# HT32F175x register map
File version: 1.1
CPU: CM3 r2p0, little endian, no MPU, no FPU, 4 interrupt priority bits
Registers are 32-bit, read-write, reset 0x0 unless marked. A register's access mark holds for its fields unless they carry their own. Offsets are from the block's base; [hi:lo] are bit positions; {n}, {i} and the like mark numbered series.

## GPTM0
Base 0x4006E000
Same registers: GPTM1 0x4006F000
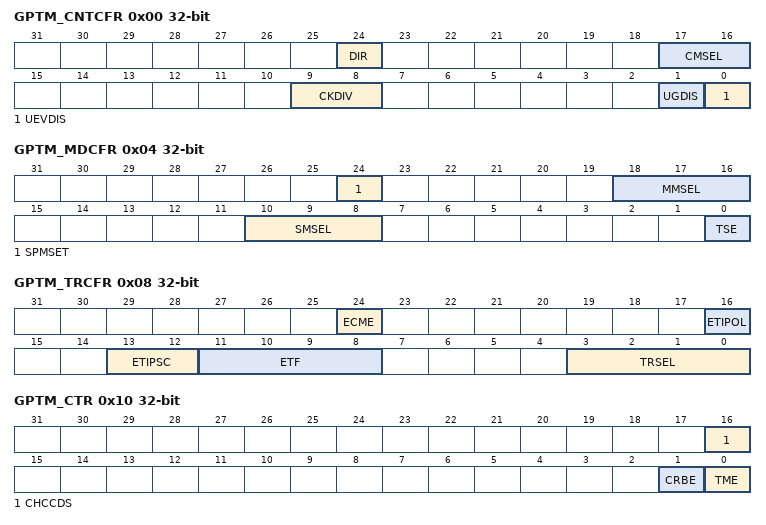
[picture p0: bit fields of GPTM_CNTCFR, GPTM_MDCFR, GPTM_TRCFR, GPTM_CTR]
0x00 GPTM_CNTCFR
  [24] DIR, [17:16] CMSEL, [9:8] CKDIV, [1] UGDIS, [0] UEVDIS
0x04 GPTM_MDCFR
  [24] SPMSET, [18:16] MMSEL, [10:8] SMSEL, [0] TSE
0x08 GPTM_TRCFR
  [24] ECME, [16] ETIPOL, [13:12] ETIPSC, [11:8] ETF, [3:0] TRSEL
0x10 GPTM_CTR
  [16] CHCCDS, [1] CRBE, [0] TME
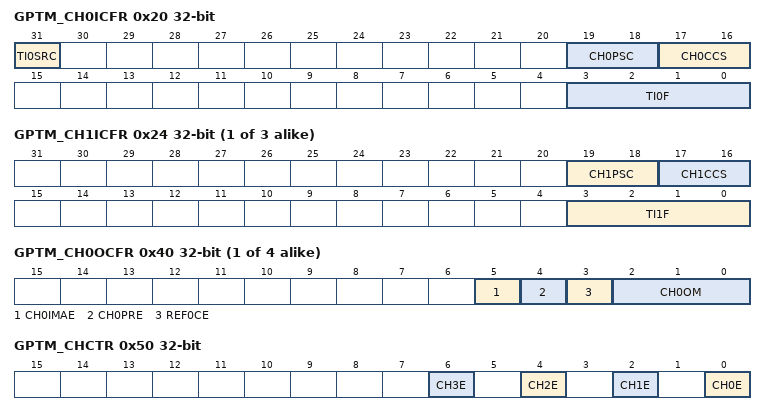
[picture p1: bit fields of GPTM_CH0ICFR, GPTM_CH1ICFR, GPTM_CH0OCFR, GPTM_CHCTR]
0x20 GPTM_CH0ICFR
  [31] TI0SRC, [19:18] CH0PSC, [17:16] CH0CCS, [3:0] TI0F
{0x20+4i} GPTM_CH{i}ICFR (i=1..3)
  [19:18] CH{i}PSC, [17:16] CH{i}CCS, [3:0] TI{i}F
{0x40+4i} GPTM_CH{i}OCFR (i=0..3)
  [5] CH{i}IMAE, [4] CH{i}PRE, [3] REF{i}CE, [2:0] CH{i}OM
0x50 GPTM_CHCTR
  [2n] CH{n}E (n=0..3)
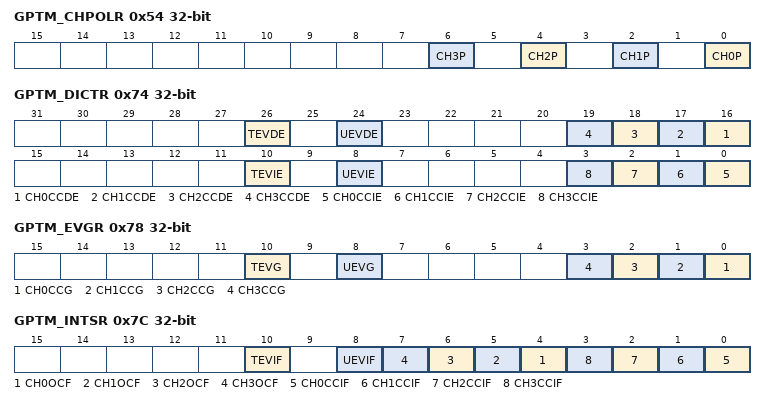
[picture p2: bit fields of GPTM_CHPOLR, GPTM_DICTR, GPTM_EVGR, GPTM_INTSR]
0x54 GPTM_CHPOLR
  [2n] CH{n}P (n=0..3)
0x74 GPTM_DICTR
  [26] TEVDE, [24] UEVDE, [n+16] CH{n}CCDE (n=0..3), [10] TEVIE, [8] UEVIE, [n] CH{n}CCIE (n=0..3)
0x78 GPTM_EVGR
  [10] TEVG, [8] UEVG, [n] CH{n}CCG (n=0..3)
0x7C GPTM_INTSR
  [10] TEVIF, [8] UEVIF, [n+4] CH{n}OCF (n=0..3), [n] CH{n}CCIF (n=0..3)
0x80 GPTM_CNTR
  [15:0] CNTV
0x84 GPTM_PSCR
  [15:0] PSCV
0x88 GPTM_CRR
  [15:0] CRV
{0x90+4i} GPTM_CH{i}CCR (i=0..3)
  [15:0] CH{i}CCV

## BFTM0
Base 0x40076000
Same registers: BFTM1 0x40077000
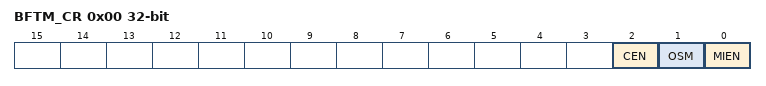
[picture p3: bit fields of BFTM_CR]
0x00 BFTM_CR
  [2] CEN, [1] OSM, [0] MIEN
0x04 BFTM_SR
  [0] MIF
0x08 BFTM_CNTR
0x0C BFTM_CMPR
  [31:0] CMP

## RTC
Base 0x4006A000
0x00 RTC_CNT
  [31:0] RTCCNT
0x04 RTC_CMP
  [31:0] RTCCMP
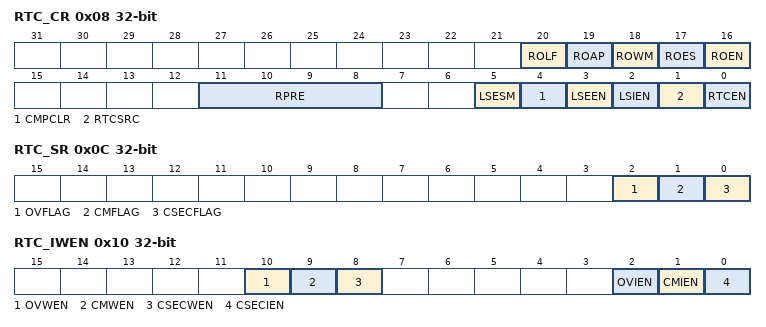
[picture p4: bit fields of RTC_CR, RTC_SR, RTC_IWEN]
0x08 RTC_CR
  [20] ROLF, [19] ROAP, [18] ROWM, [17] ROES, [16] ROEN, [11:8] RPRE, [5] LSESM, [4] CMPCLR, [3] LSEEN, [2] LSIEN, [1] RTCSRC, [0] RTCEN
0x0C RTC_SR
  [2] OVFLAG, [1] CMFLAG, [0] CSECFLAG
0x10 RTC_IWEN
  [10] OVWEN, [9] CMWEN, [8] CSECWEN, [2] OVIEN, [1] CMIEN, [0] CSECIEN

## WDT
Base 0x40068000
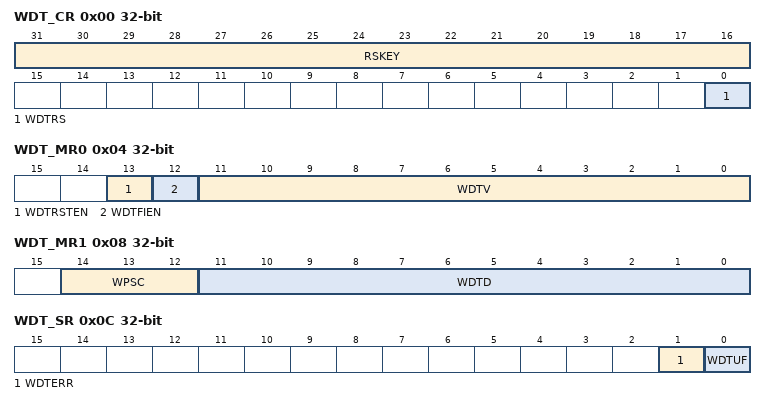
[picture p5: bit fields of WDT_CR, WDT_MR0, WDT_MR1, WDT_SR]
0x00 WDT_CR
  [31:16] RSKEY, [0] WDTRS
0x04 WDT_MR0
  [13] WDTRSTEN, [12] WDTFIEN, [11:0] WDTV
0x08 WDT_MR1
  [14:12] WPSC, [11:0] WDTD
0x0C WDT_SR
  [1] WDTERR, [0] WDTUF
0x10 WDT_PR
  [15:0] PROTECT

## I2C0
Base 0x40048000
Same registers: I2C1 0x40049000
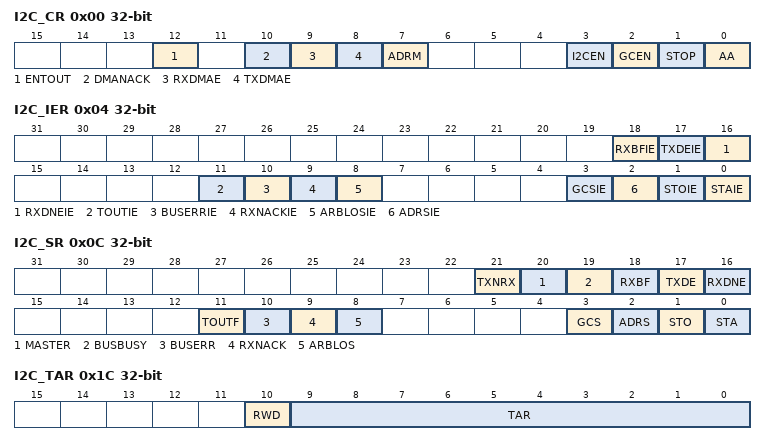
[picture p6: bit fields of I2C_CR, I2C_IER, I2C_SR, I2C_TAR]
0x00 I2C_CR
  [12] ENTOUT, [10] DMANACK, [9] RXDMAE, [8] TXDMAE, [7] ADRM, [3] I2CEN, [2] GCEN, [1] STOP, [0] AA
0x04 I2C_IER
  [18] RXBFIE, [17] TXDEIE, [16] RXDNEIE, [11] TOUTIE, [10] BUSERRIE, [9] RXNACKIE, [8] ARBLOSIE, [3] GCSIE, [2] ADRSIE, [1] STOIE, [0] STAIE
0x08 I2C_ADDR
  [9:0] ADDR
0x0C I2C_SR
  [21] TXNRX, [20] MASTER, [19] BUSBUSY, [18] RXBF, [17] TXDE, [16] RXDNE, [11] TOUTF, [10] BUSERR, [9] RXNACK, [8] ARBLOS, [3] GCS, [2] ADRS, [1] STO, [0] STA
0x10 I2C_SHPGR
  [15:0] SHPG
0x14 I2C_SLPGR
  [15:0] SLPG
0x18 I2C_DR
  [7:0] DATA
0x1C I2C_TAR
  [10] RWD, [9:0] TAR
0x20 I2C_ADDMR
  [9:0] ADDMR
0x24 I2C_ADDSR
  [9:0] ADDSR
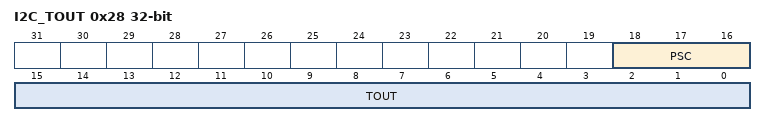
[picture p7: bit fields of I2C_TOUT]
0x28 I2C_TOUT
  [18:16] PSC, [15:0] TOUT

## SPI0
Base 0x40004000
Same registers: SPI1 0x40044000
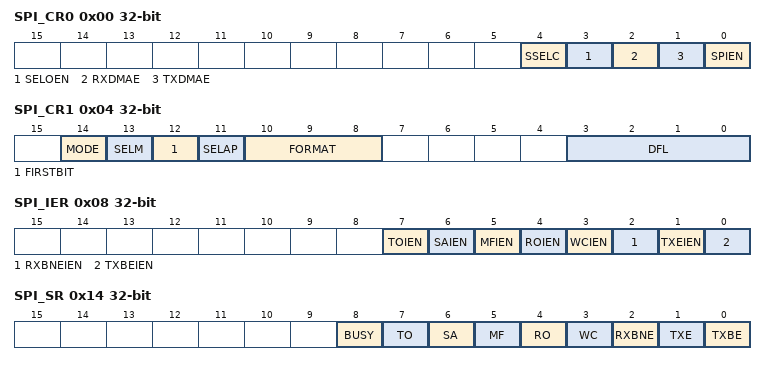
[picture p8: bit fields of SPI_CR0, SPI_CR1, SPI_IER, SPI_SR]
0x00 SPI_CR0
  [4] SSELC, [3] SELOEN, [2] RXDMAE, [1] TXDMAE, [0] SPIEN
0x04 SPI_CR1
  [14] MODE, [13] SELM, [12] FIRSTBIT, [11] SELAP, [10:8] FORMAT, [3:0] DFL
0x08 SPI_IER
  [7] TOIEN, [6] SAIEN, [5] MFIEN, [4] ROIEN, [3] WCIEN, [2] RXBNEIEN, [1] TXEIEN, [0] TXBEIEN
0x0C SPI_CPR
  [15:0] CP
0x10 SPI_DR
  [15:0] DR
0x14 SPI_SR
  [8] BUSY, [7] TO, [6] SA, [5] MF, [4] RO, [3] WC, [2] RXBNE, [1] TXE, [0] TXBE
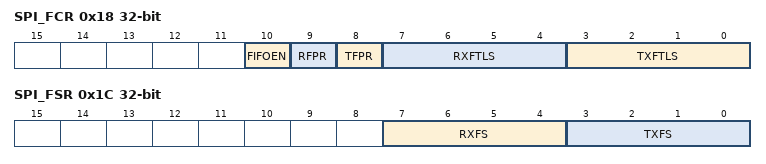
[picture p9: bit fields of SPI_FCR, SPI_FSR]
0x18 SPI_FCR
  [10] FIFOEN, [9] RFPR, [8] TFPR, [7:4] RXFTLS, [3:0] TXFTLS
0x1C SPI_FSR
  [7:4] RXFS, [3:0] TXFS
0x20 SPI_FTOCR
  [31:0] TOC

## USART0
Base 0x40000000
0x00 USART0_RBR
  [8:0] RD
0x00 USART0_TBR (USART0 view)
  [8:0] TD
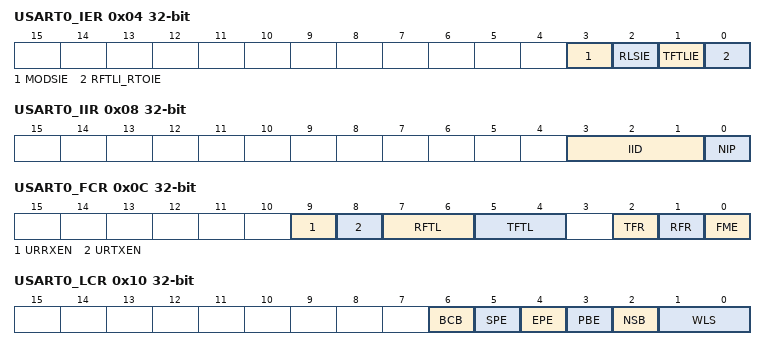
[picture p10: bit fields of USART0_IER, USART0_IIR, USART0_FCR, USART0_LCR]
0x04 USART0_IER
  [3] MODSIE, [2] RLSIE, [1] TFTLIE, [0] RFTLI_RTOIE
0x08 USART0_IIR
  [3:1] IID, [0] NIP
0x0C USART0_FCR
  [9] URRXEN, [8] URTXEN, [7:6] RFTL, [5:4] TFTL, [2] TFR, [1] RFR, [0] FME
0x10 USART0_LCR
  [6] BCB, [5] SPE, [4] EPE, [3] PBE, [2] NSB, [1:0] WLS
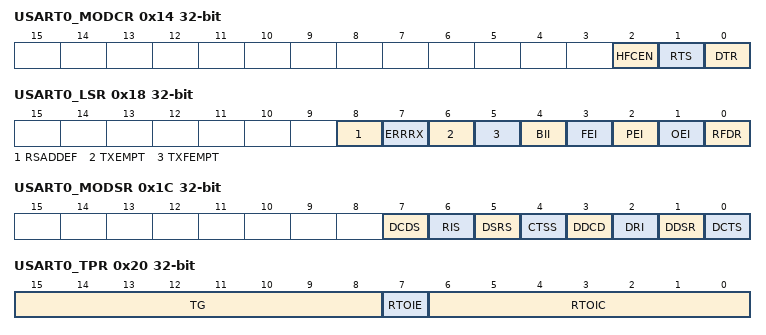
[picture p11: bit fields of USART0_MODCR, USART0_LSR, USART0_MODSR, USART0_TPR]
0x14 USART0_MODCR
  [2] HFCEN, [1] RTS, [0] DTR
0x18 USART0_LSR
  [8] RSADDEF, [7] ERRRX, [6] TXEMPT, [5] TXFEMPT, [4] BII, [3] FEI, [2] PEI, [1] OEI, [0] RFDR
0x1C USART0_MODSR
  [7] DCDS, [6] RIS, [5] DSRS, [4] CTSS, [3] DDCD, [2] DRI, [1] DDSR, [0] DCTS
0x20 USART0_TPR
  [15:8] TG, [7] RTOIE, [6:0] RTOIC
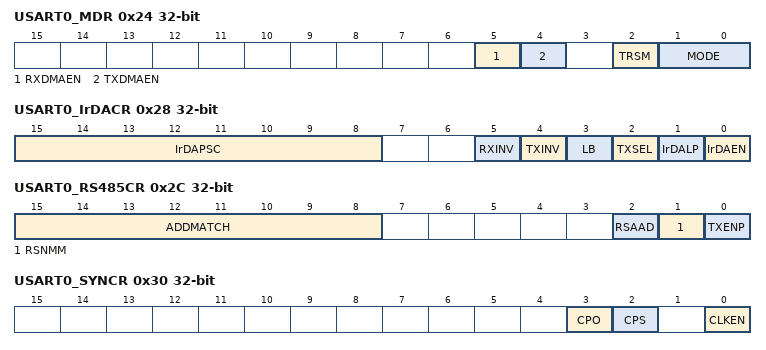
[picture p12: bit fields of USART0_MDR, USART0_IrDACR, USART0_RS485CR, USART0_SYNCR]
0x24 USART0_MDR
  [5] RXDMAEN, [4] TXDMAEN, [2] TRSM, [1:0] MODE
0x28 USART0_IrDACR
  [15:8] IrDAPSC, [5] RXINV, [4] TXINV, [3] LB, [2] TXSEL, [1] IrDALP, [0] IrDAEN
0x2C USART0_RS485CR
  [15:8] ADDMATCH, [2] RSAAD, [1] RSNMM, [0] TXENP
0x30 USART0_SYNCR
  [3] CPO, [2] CPS, [0] CLKEN
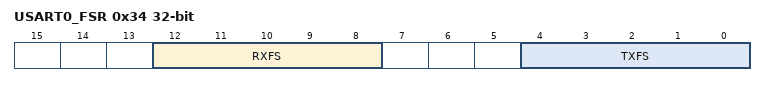
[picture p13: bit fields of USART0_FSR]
0x34 USART0_FSR
  [12:8] RXFS, [4:0] TXFS
0x38 USART0_DLR
  [15:0] BRD
0x40 USART0_DEGTSTR
  [1:0] LBM

## USART1
Base 0x40040000
Registers as USART0 (with USART0 read as USART1).

## Notices in the file
Copyright (C) 2010 ARM Limited. All rights reserved.
ARM Limited (ARM) is supplying this SVD description for use with Cortex-M3
processor based microcontrollers.  This file and or content can be freely
distributed within development tools that are supporting such ARM based
processors.
THIS SOFTWARE IS PROVIDED "AS IS".  NO WARRANTIES, WHETHER EXPRESS, IMPLIED
OR STATUTORY, INCLUDING, BUT NOT LIMITED TO, IMPLIED WARRANTIES OF
MERCHANTABILITY AND FITNESS FOR A PARTICULAR PURPOSE APPLY TO THIS SOFTWARE.
ARM SHALL NOT, IN ANY CIRCUMSTANCES, BE LIABLE FOR SPECIAL, INCIDENTAL, OR
CONSEQUENTIAL DAMAGES, FOR ANY REASON WHATSOEVER.
